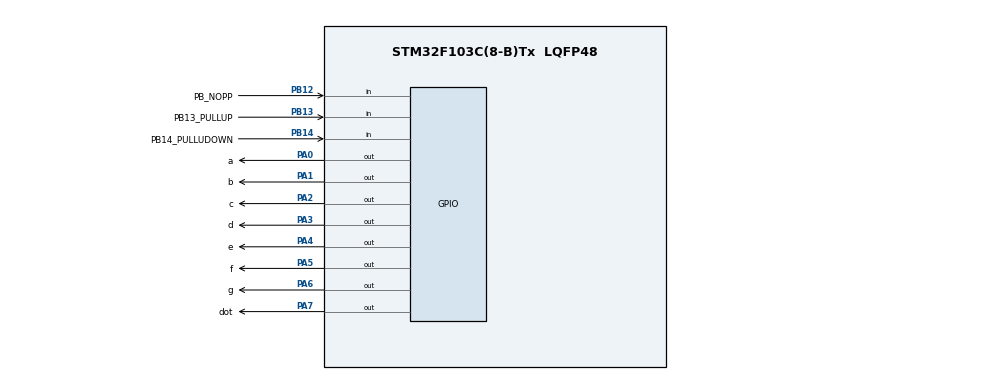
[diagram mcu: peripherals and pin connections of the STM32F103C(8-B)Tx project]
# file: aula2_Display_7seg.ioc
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Mcu.Family=STM32F1
Mcu.Name=STM32F103C(8-B)Tx
Mcu.Package=LQFP48
NVIC.PriorityGroup=NVIC_PRIORITYGROUP_4
PA0-WKUP.GPIO_Label=a
PA0-WKUP.Signal=GPIO_Output
PA1.GPIO_Label=b
PA1.Signal=GPIO_Output
PA13.Mode=Serial_Wire
PA13.Signal=SYS_JTMS-SWDIO
PA14.Mode=Serial_Wire
PA14.Signal=SYS_JTCK-SWCLK
PA2.GPIO_Label=c
PA2.Signal=GPIO_Output
PA3.GPIO_Label=d
PA3.Signal=GPIO_Output
PA4.GPIO_Label=e
PA4.Signal=GPIO_Output
PA5.GPIO_Label=f
PA5.Signal=GPIO_Output
PA6.GPIO_Label=g
PA6.Signal=GPIO_Output
PA7.GPIO_Label=dot
PA7.Signal=GPIO_Output
PB12.GPIO_Label=PB_NOPP
PB12.Signal=GPIO_Input
PB13.GPIO_Label=PB13_PULLUP
PB13.GPIO_PuPd=GPIO_PULLUP
PB13.Signal=GPIO_Input
PB14.GPIO_Label=PB14_PULLUDOWN
PB14.GPIO_PuPd=GPIO_PULLDOWN
PB14.Signal=GPIO_Input
ProjectManager.HeapSize=0x200
ProjectManager.StackSize=0x400
ProjectManager.TargetToolchain=STM32CubeIDE
RCC.APB1Freq_Value=8000000
RCC.APB2Freq_Value=8000000
board=custom

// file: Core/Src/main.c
/* USER CODE BEGIN Header */
/**
  ******************************************************************************
  * @file           : main.c
  * @brief          : Main program body
  ******************************************************************************
  * @attention
  *
  * Copyright (c) 2022 STMicroelectronics.
  * All rights reserved.
  *
  * This software is licensed under terms that can be found in the LICENSE file
  * in the root directory of this software component.
  * If no LICENSE file comes with this software, it is provided AS-IS.
  *
  ******************************************************************************
  */
/* USER CODE END Header */
#include "main.h"

void SystemClock_Config(void);
static void MX_GPIO_Init(void);

int main(void)
{

  /* MCU Configuration--------------------------------------------------------*/

  /* Reset of all peripherals, Initializes the Flash interface and the Systick. */
  HAL_Init();

  /* Configure the system clock */
  SystemClock_Config();

  /* Initialize all configured peripherals */
  MX_GPIO_Init();

  /* Infinite loop */
  /* USER CODE BEGIN WHILE */
  while (1)
  {

	  if(HAL_GPIO_ReadPin(PB12_NOPP_GPIO_Port *GPIOA, unit16_t PB_NOPP_Pin) == PB14_PULLUDOWN_GPIO_Port){
		  GPIOA->ODR = 0x0039 && GPIOA->ODR;
	  }else{
		  GPIOA->ODR = 0x0000;
	  }

	  if(HAL_GPIO_ReadPin(PB13_PULLUP_GPIO_Port *GPIOA, unit16_t PB_NOPP_Pin) == PB14_PULLUDOWN_GPIO_Port){
		  GPIOA->ODR = 0x005E;
	  }else{
		  GPIOA->ODR = 0x0000;
	  }

	// DISPLAY 7 SEGMENTOS
/*	GPIOA->ODR = 0x003F; // 0
	HAL_Delay(1000);
	GPIOA->ODR = 0x0006; // 1
	HAL_Delay(1000);
	GPIOA->ODR = 0x005B; // 2
	HAL_Delay(1000);
	GPIOA->ODR = 0x004F; // 3
	HAL_Delay(1000);
	GPIOA->ODR = 0x0066; // 4
	HAL_Delay(1000);
	GPIOA->ODR = 0x006D; // 5
	HAL_Delay(1000);
	GPIOA->ODR = 0x007D; // 6
	HAL_Delay(1000);
	GPIOA->ODR = 0x0007; // 7
	HAL_Delay(1000);
	GPIOA->ODR = 0x007F; // 8
	HAL_Delay(1000);
	GPIOA->ODR = 0x006F; // 9
	HAL_Delay(1000);
	GPIOA->ODR = 0x0077; // a
	HAL_Delay(1000);
	GPIOA->ODR = 0x007C; // b
	HAL_Delay(1000);
	GPIOA->ODR = 0x0039; // c
	HAL_Delay(1000);
	GPIOA->ODR = 0x005E; // d
	HAL_Delay(1000);
	GPIOA->ODR = 0x0079; // e
	HAL_Delay(1000);
	GPIOA->ODR = 0x0071; // f
	HAL_Delay(1000);*/

    /* USER CODE END WHILE */

  }
}

void SystemClock_Config(void)
{
  RCC_OscInitTypeDef RCC_OscInitStruct = {0};
  RCC_ClkInitTypeDef RCC_ClkInitStruct = {0};

  /** Initializes the RCC Oscillators according to the specified parameters
  * in the RCC_OscInitTypeDef structure.
  */
  RCC_OscInitStruct.OscillatorType = RCC_OSCILLATORTYPE_HSI;
  RCC_OscInitStruct.HSIState = RCC_HSI_ON;
  RCC_OscInitStruct.HSICalibrationValue = RCC_HSICALIBRATION_DEFAULT;
  RCC_OscInitStruct.PLL.PLLState = RCC_PLL_NONE;
  if (HAL_RCC_OscConfig(&RCC_OscInitStruct) != HAL_OK)
  {
    Error_Handler();
  }

  /** Initializes the CPU, AHB and APB buses clocks
  */
  RCC_ClkInitStruct.ClockType = RCC_CLOCKTYPE_HCLK|RCC_CLOCKTYPE_SYSCLK
                              |RCC_CLOCKTYPE_PCLK1|RCC_CLOCKTYPE_PCLK2;
  RCC_ClkInitStruct.SYSCLKSource = RCC_SYSCLKSOURCE_HSI;
  RCC_ClkInitStruct.AHBCLKDivider = RCC_SYSCLK_DIV1;
  RCC_ClkInitStruct.APB1CLKDivider = RCC_HCLK_DIV1;
  RCC_ClkInitStruct.APB2CLKDivider = RCC_HCLK_DIV1;

  if (HAL_RCC_ClockConfig(&RCC_ClkInitStruct, FLASH_LATENCY_0) != HAL_OK)
  {
    Error_Handler();
  }
}

static void MX_GPIO_Init(void)
{
  GPIO_InitTypeDef GPIO_InitStruct = {0};

  /* GPIO Ports Clock Enable */
  __HAL_RCC_GPIOA_CLK_ENABLE();
  __HAL_RCC_GPIOB_CLK_ENABLE();

  /*Configure GPIO pin Output Level */
  HAL_GPIO_WritePin(GPIOA, a_Pin|b_Pin|c_Pin|d_Pin
                          |e_Pin|f_Pin|g_Pin|dot_Pin, GPIO_PIN_RESET);

  /*Configure GPIO pins : a_Pin b_Pin c_Pin d_Pin
                           e_Pin f_Pin g_Pin dot_Pin */
  GPIO_InitStruct.Pin = a_Pin|b_Pin|c_Pin|d_Pin
                          |e_Pin|f_Pin|g_Pin|dot_Pin;
  GPIO_InitStruct.Mode = GPIO_MODE_OUTPUT_PP;
  GPIO_InitStruct.Pull = GPIO_NOPULL;
  GPIO_InitStruct.Speed = GPIO_SPEED_FREQ_LOW;
  HAL_GPIO_Init(GPIOA, &GPIO_InitStruct);

  /*Configure GPIO pin : PB_NOPP_Pin */
  GPIO_InitStruct.Pin = PB_NOPP_Pin;
  GPIO_InitStruct.Mode = GPIO_MODE_INPUT;
  GPIO_InitStruct.Pull = GPIO_NOPULL;
  HAL_GPIO_Init(PB_NOPP_GPIO_Port, &GPIO_InitStruct);

  /*Configure GPIO pin : PB13_PULLUP_Pin */
  GPIO_InitStruct.Pin = PB13_PULLUP_Pin;
  GPIO_InitStruct.Mode = GPIO_MODE_INPUT;
  GPIO_InitStruct.Pull = GPIO_PULLUP;
  HAL_GPIO_Init(PB13_PULLUP_GPIO_Port, &GPIO_InitStruct);

  /*Configure GPIO pin : PB14_PULLUDOWN_Pin */
  GPIO_InitStruct.Pin = PB14_PULLUDOWN_Pin;
  GPIO_InitStruct.Mode = GPIO_MODE_INPUT;
  GPIO_InitStruct.Pull = GPIO_PULLDOWN;
  HAL_GPIO_Init(PB14_PULLUDOWN_GPIO_Port, &GPIO_InitStruct);

}

void Error_Handler(void)
{
  __disable_irq();
  while (1)
  {
  }
}
